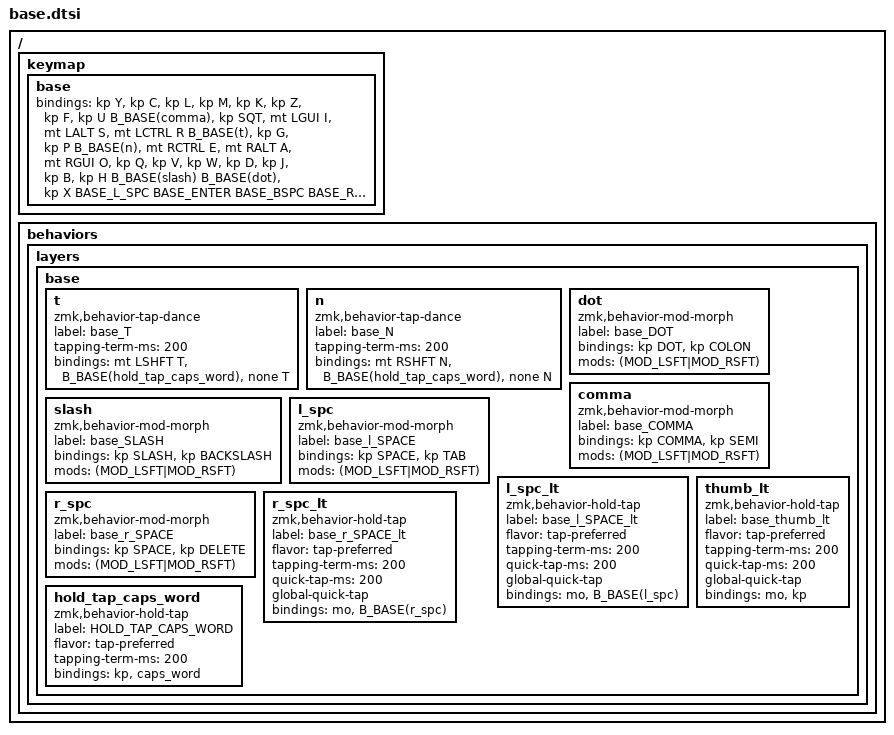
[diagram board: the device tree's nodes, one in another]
// Copyright (c) 2022 The ZMK Contributors
// SPDX-License-Identifier: MIT

#define B_BASE(key) B_LAYER(base, key)

#define BASE_L_SPC B_BASE(l_spc_lt) L_BRACKET 0
#define BASE_ENTER B_BASE(thumb_lt) L_NAV     ENTER
#define BASE_BSPC  B_BASE(thumb_lt) L_NUM     BSPC
#define BASE_R_SPC B_BASE(r_spc_lt) L_SYM     0

/ {
    keymap {
        base {
            bindings = <
        // ╭──────────────┬──────────────┬──────────────┬──────────────┬──────────────╮   ╭──────────────┬──────────────┬──────────────┬──────────────┬──────────────╮
        // │  Y           │  C           │  L           │  M           │  K           │   │  Z           │  F           │  U           │  ,;          │  '"          │
             &kp Y          &kp C          &kp L          &kp M          &kp K              &kp Z          &kp F          &kp U          B_BASE(comma)  &kp SQT    
        // ├──────────────┼──────────────┼──────────────┼──────────────┼──────────────┤   ├──────────────┼──────────────┼──────────────┼──────────────┼──────────────┤
        // │  I           │  S           │  R           │  T           │  G           │   │  P           │  N           │  E           │  A           │  O           │
             &mt LGUI I     &mt LALT S     &mt LCTRL R    B_BASE(t)      &kp G              &kp P          B_BASE(n)      &mt RCTRL E    &mt RALT A     &mt RGUI O 
        // ├──────────────┼──────────────┼──────────────┼──────────────┼──────────────┤   ├──────────────┼──────────────┼──────────────┼──────────────┼──────────────┤
        // │  Q           │  V           │  W           │  D           │  J           │   │  B           │  H           │  /\          │  .:          │  X           │
             &kp Q          &kp V          &kp W          &kp D          &kp J              &kp B          &kp H          B_BASE(slash)  B_BASE(dot)    &kp X      
        // ╰──────────────┴──────────────┴──────────────┼──────────────┼──────────────┤   ├──────────────┼──────────────┼──────────────┴──────────────┴──────────────╯
        //                                              |  SPACE       |  ENTER       |   |  BACKSPACE   |  SPACE       |
                                                          BASE_L_SPC     BASE_ENTER         BASE_BSPC      BASE_R_SPC
        //                                              ╰──────────────┴──────────────╯   ╰──────────────┴──────────────╯
            >;
        };
    };

    behaviors {
        layers {
            base {
                t {
                    compatible = "zmk,behavior-tap-dance";
                    label = "base_T";
                    #binding-cells = <0>;
                    tapping-term-ms = <200>;
                    bindings = <&mt LSHFT T>, <B_BASE(hold_tap_caps_word) &none T>;
                };

                n {
                    compatible = "zmk,behavior-tap-dance";
                    label = "base_N";
                    #binding-cells = <0>;
                    tapping-term-ms = <200>;
                    bindings = <&mt RSHFT N>, <B_BASE(hold_tap_caps_word) &none N>;
                };

                dot {
                    compatible = "zmk,behavior-mod-morph";
                    label = "base_DOT";
                    #binding-cells = <0>;
                    bindings = <&kp DOT>, <&kp COLON>;
                    mods = <(MOD_LSFT|MOD_RSFT)>;
                };

                comma {
                    compatible = "zmk,behavior-mod-morph";
                    label = "base_COMMA";
                    #binding-cells = <0>;
                    bindings = <&kp COMMA>, <&kp SEMI>;
                    mods = <(MOD_LSFT|MOD_RSFT)>;
                };

                slash {
                    compatible = "zmk,behavior-mod-morph";
                    label = "base_SLASH";
                    #binding-cells = <0>;
                    bindings = <&kp SLASH>, <&kp BACKSLASH>;
                    mods = <(MOD_LSFT|MOD_RSFT)>;
                };

                l_spc {
                    compatible = "zmk,behavior-mod-morph";
                    label = "base_l_SPACE";
                    #binding-cells = <0>;
                    bindings = <&kp SPACE>, <&kp TAB>;
                    mods = <(MOD_LSFT|MOD_RSFT)>;
                };

                l_spc_lt {
                    compatible = "zmk,behavior-hold-tap";
                    label = "base_l_SPACE_lt";
                    #binding-cells = <2>;
                    flavor = "tap-preferred";
                    tapping-term-ms = <200>;
                    quick-tap-ms = <200>;
                    global-quick-tap;
                    bindings = <&mo>, <B_BASE(l_spc)>;
                };

                r_spc {
                    compatible = "zmk,behavior-mod-morph";
                    label = "base_r_SPACE";
                    #binding-cells = <0>;
                    bindings = <&kp SPACE>, <&kp DELETE>;
                    mods = <(MOD_LSFT|MOD_RSFT)>;
                };

                r_spc_lt {
                    compatible = "zmk,behavior-hold-tap";
                    label = "base_r_SPACE_lt";
                    #binding-cells = <2>;
                    flavor = "tap-preferred";
                    tapping-term-ms = <200>;
                    quick-tap-ms = <200>;
                    global-quick-tap;
                    bindings = <&mo>, <B_BASE(r_spc)>;
                };

                thumb_lt {
                    compatible = "zmk,behavior-hold-tap";
                    label = "base_thumb_lt";
                    #binding-cells = <2>;
                    flavor = "tap-preferred";
                    tapping-term-ms = <200>;
                    quick-tap-ms = <200>;
                    global-quick-tap;
                    bindings = <&mo>, <&kp>;
                };

                hold_tap_caps_word {
                  compatible = "zmk,behavior-hold-tap";
                  label = "HOLD_TAP_CAPS_WORD";
                  #binding-cells = <2>;
                  flavor = "tap-preferred";
                  tapping-term-ms = <200>;
                  bindings = <&kp>, <&caps_word>;
                };
            };
        };
    };
};
